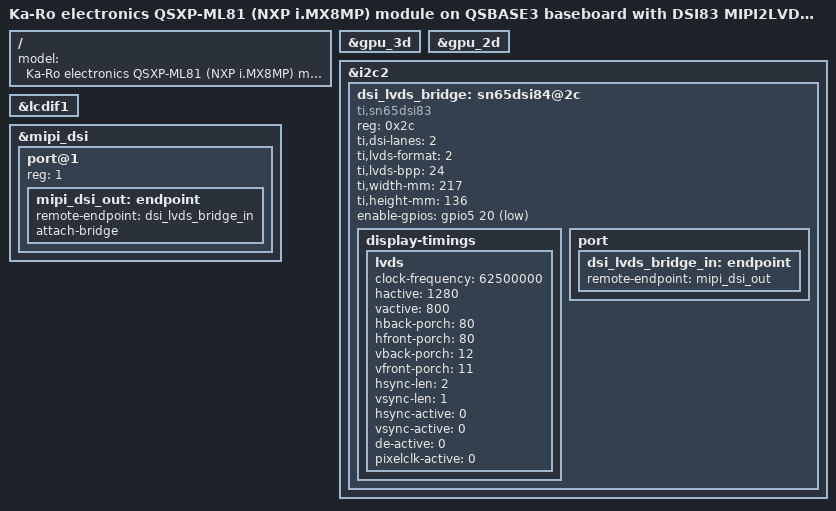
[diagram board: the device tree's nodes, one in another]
// SPDX-License-Identifier: (GPL-2.0 OR MIT)
/*
 * Copyright (C) 2020 Markus Bauer <mb@karo-electronics.de>
 *
 */

/dts-v1/;

#include "imx8mp-qsxp-ml81.dts"
#include "imx8mp-qsxp-ml81-qsbase3.dtsi"

/ {
	model = "Ka-Ro electronics QSXP-ML81 (NXP i.MX8MP) module on QSBASE3 baseboard with DSI83 MIPI2LVDS converter";
};

&gpu_3d {
	status = "okay";
};

&gpu_2d {
	status = "okay";
};

&i2c2 {
	dsi_lvds_bridge: sn65dsi84@2c {
		compatible = "ti,sn65dsi83";
		reg = <0x2c>;
		ti,dsi-lanes = <2>;
		ti,lvds-format = <2>;
		ti,lvds-bpp = <24>;
		ti,width-mm = <217>;
		ti,height-mm = <136>;
		enable-gpios = <&gpio5 20 GPIO_ACTIVE_LOW>;
		status = "okay";

		display-timings {
			lvds {
				clock-frequency = <62500000>;
				hactive = <1280>;
				vactive = <800>;
				hback-porch = <80>;
				hfront-porch = <80>;
				vback-porch = <12>;
				vfront-porch = <11>;
				hsync-len = <2>;
				vsync-len = <1>;
				hsync-active = <0>;
				vsync-active = <0>;
				de-active = <0>;
				pixelclk-active = <0>;
			};
		};

		port {
			dsi_lvds_bridge_in: endpoint {
				remote-endpoint = <&mipi_dsi_out>;
			};
		};
	};
};

&lcdif1 {
	status = "okay";
};

&mipi_dsi {
	status = "okay";

	port@1 {
		reg = <1>;

		mipi_dsi_out: endpoint {
			remote-endpoint = <&dsi_lvds_bridge_in>;
			attach-bridge;
		};
	};
};
